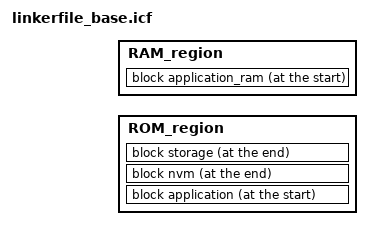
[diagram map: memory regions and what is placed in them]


/*###ICF### Section handled by ICF editor, don't touch! ****/
/*-Editor annotation file-*/
/* IcfEditorFile="$TOOLKIT_DIR$\config\ide\IcfEditor\cortex_v1_0.xml" */
/* Version 4.1.1 */

/*-Memory Regions-*/
define symbol __ICFEDIT_region_ROM_start__ = 0x8006000;
define symbol __ICFEDIT_region_ROM_end__   = (0x8006000+0x178000-1);
define symbol __ICFEDIT_region_RAM_start__ = 0x20000000;
define symbol __ICFEDIT_region_RAM_end__   = (0x20000000+0x40000-1);

/**** End of ICF editor section. ###ICF###*/

define memory mem with size = 4G;
define region ROM_region   = mem:[from __ICFEDIT_region_ROM_start__   to __ICFEDIT_region_ROM_end__];
define region RAM_region   = mem:[from __ICFEDIT_region_RAM_start__   to __ICFEDIT_region_RAM_end__];

define block CSTACK with alignment = 8
{
  section .stack
};

define block HEAP with alignment = 8
{
  section .heap
};

define block header with alignment = 8
{
  section AAT
};

define block nvm with alignment = 8192
{
  section SIMEE,
};
keep { block nvm };

define block storage with alignment = 8192
{
  section INTERNAL_STORAGE,
};
keep { block storage };

define block application with fixed order
{
  block header,
  readonly section .intvec,
  readonly
};

define block application_ram with fixed order
{
  block CSTACK,
  readwrite,
  block HEAP
};

initialize by copy { readwrite };

do not initialize
{
 section .noinit,
 section .stack,
 section .heap
};

keep {
  section .intvec,
  section AAT,
  block header
};
"application":
place at start of ROM_region { block application };

"storage_regions":
place at end of ROM_region {
  block nvm,
  block storage
};

"application_ram":
place at start of RAM_region { block application_ram };
